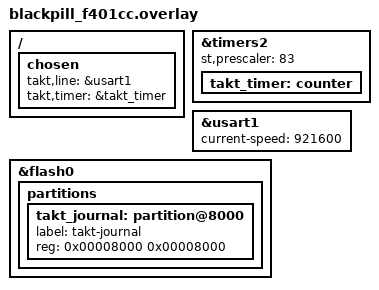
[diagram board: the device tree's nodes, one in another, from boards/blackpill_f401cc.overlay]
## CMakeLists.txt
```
# Takt unter Zephyr (12.11, M11 Schritt 19): das Pruefprogramm der
# Portpruefung als Baustein einer Zephyr-Anwendung, auf `blackpill_f401cc`
# und `esp32c6_devkitc/esp32c6/hpcore`.
#
#   west build -b blackpill_f401cc examples/zephyr --
#       -DTAKT_EXECUTABLE=<takt> -DTAKT_SDK_LIBRARY=<SDK-Archiv des Ziels>
#
# Das SDK-Archiv ist fuer das Tripel aus `CONFIG_TAKT_TARGET` gebaut
# (`cargo rustc --release --lib --crate-type staticlib --target TRIPEL
# --manifest-path crates/takt-embed-c/Cargo.toml`). Das Modul ist die Wurzel
# von Takt (`zephyr/module.yml`); eine Anwendung ausserhalb nimmt es ueber
# ihr west-Manifest oder `ZEPHYR_EXTRA_MODULES`.

cmake_minimum_required(VERSION 3.20.0)

set(TAKT_ROOT ${CMAKE_CURRENT_LIST_DIR}/../..)
list(APPEND ZEPHYR_EXTRA_MODULES ${TAKT_ROOT})
find_package(Zephyr REQUIRED HINTS $ENV{ZEPHYR_BASE})
project(takt_zephyr C)

# Die Hardware-Konfiguration des Boards (8.10): Kalibrierung, Stack-Reserve
# der Form `rtos`, Journal.
if(BOARD STREQUAL "blackpill_f401cc")
  set(hardware ${TAKT_ROOT}/corpus-try/hw/stm32f401.hw)
elseif(BOARD STREQUAL "esp32c6_devkitc")
  set(hardware ${TAKT_ROOT}/corpus-try/hw/esp32c6.hw)
else()
  message(FATAL_ERROR "examples/zephyr: keine Hardware-Konfiguration fuer ${BOARD}")
endif()

# Im Sim-Build, wie `takt port-test --emit embed` es liefert: Die Ausgaenge
# gehen ohne Treiber in den Trace.
takt_add_program(port_test SOURCE ${TAKT_ROOT}/corpus-try/124_port_test.takt HARDWARE ${hardware} BUILD sim)

target_sources(app PRIVATE src/main.c src/line.c src/handback.c src/partition.c)
if(BOARD STREQUAL "blackpill_f401cc")
  target_sources(app PRIVATE src/handback_stm32f401.c)
else()
  target_sources(app PRIVATE src/handback_reboot.c)
endif()
target_link_libraries(app PRIVATE port_test)

# Ein frisches Journal fuer die Portpruefung, die mit dem Interpreter ohne
# gespeicherte Werte vergleicht; ohne ueberlebt `persist` einen Neustart.
option(TAKT_FRESH_JOURNAL "das Journal vor dem Lauf loeschen" OFF)
if(TAKT_FRESH_JOURNAL)
  target_compile_definitions(app PRIVATE TAKT_FRESH_JOURNAL=1)
else()
  target_compile_definitions(app PRIVATE TAKT_FRESH_JOURNAL=0)
endif()

# Eine zweite Probe der Partition im Lauf: Der Kern meldet sie als
# `Runtime(Hardware)` (12.3); fuer den Board-Test, nicht fuer die Portpruefung.
option(TAKT_PROBE_IN_RUN "die Partition auch im Lauf proben" OFF)
if(TAKT_PROBE_IN_RUN)
  target_compile_definitions(app PRIVATE TAKT_PROBE_IN_RUN=1)
else()
  target_compile_definitions(app PRIVATE TAKT_PROBE_IN_RUN=0)
endif()
```

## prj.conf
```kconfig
# Takt unter Zephyr (12.11): das Modul, die Leitung und die fremde Last.
CONFIG_TAKT=y

# Das Journal (5.9) im Flash, in der Partition `takt_journal` des
# Devicetree (boards/*.overlay).
CONFIG_TAKT_JOURNAL_FLASH=y

# Die Leitung (12.2, 12.5): das UART-Geraet `takt,line` des Devicetree,
# gesendet aus seinem Interrupt, damit der Schritt nie auf sie wartet.
CONFIG_SERIAL=y
CONFIG_UART_INTERRUPT_DRIVEN=y
CONFIG_RING_BUFFER=y

# Die Arena in einer eigenen Partition, die keine Domaene eines Fadens im
# Benutzermodus enthaelt (12.11, `Schutz: Partition`).
CONFIG_USERSPACE=y

# Die Uhr des Ports ist ein Zaehler, den boards/*.overlay als `takt,timer`
# waehlt (FB-733); ohne ihn waere die Frist auf einen Systemtick genau.
CONFIG_COUNTER=y
CONFIG_SYS_CLOCK_TICKS_PER_SEC=100000

# `main` rechnet die fremde Last unter dem Jobfaden und schreibt am Ende die
# Bilanz (`takt_core_report`).
CONFIG_MAIN_THREAD_PRIORITY=14
CONFIG_MAIN_STACK_SIZE=4096
```

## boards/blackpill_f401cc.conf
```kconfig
# Board 1 (plan/f401.md): Sektor 0 haelt der HID-Bootloader, Sektor 1 das
# Sprungbrett, Sektor 2 und 3 das Journal; die Anwendung beginnt in Sektor 4
# (0x0801_0000), wo das Sprungbrett sie startet, und hat 192 KiB.
CONFIG_FLASH_LOAD_OFFSET=0x10000
CONFIG_FLASH_LOAD_SIZE=0x30000

# Die FPU mit der ABI des Tripels `thumbv7em-none-eabihf`; `CONFIG_TAKT`
# waehlt dazu `CONFIG_FPU_SHARING`.
CONFIG_FPU=y
CONFIG_FP_HARDABI=y

# USART1 ist die Leitung, keine Konsole daneben.
CONFIG_CONSOLE=n
CONFIG_UART_CONSOLE=n
```

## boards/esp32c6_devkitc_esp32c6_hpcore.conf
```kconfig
# Board 2: `TAKT` auf der Leitung startet das Board neu (src/handback_reboot.c).
CONFIG_REBOOT=y
```

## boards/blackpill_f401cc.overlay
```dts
/* Board 1: die Leitung auf USART1 (PA9/PA10) mit der Rate aller
 * F401-Programme, die der Host ohne Wissen um das laufende erreicht, und
 * TIM2 als Uhr des Ports. Das
 * Journal in Sektor 2 und 3 (je 16 KiB ab 0x0800_8000), wo es auch die
 * Bring-ups halten: zwischen Sprungbrett und Anwendung, und kein Abbild
 * schreibt dorthin. */
/ {
	chosen {
		takt,line = &usart1;
		takt,timer = &takt_timer;
	};
};

/* Die Uhr des Ports (FB-733): TIM2, 32 Bit, mit 1 MHz wie die
 * Interruptform in Rust (`takt_board_stm32f401::TIMER_HZ`); 84 MHz
 * Timertakt durch 84. */
&timers2 {
	st,prescaler = <83>;
	status = "okay";

	takt_timer: counter {
		status = "okay";
	};
};

&usart1 {
	current-speed = <921600>;
};

&flash0 {
	partitions {
		takt_journal: partition@8000 {
			label = "takt-journal";
			reg = <0x00008000 0x00008000>;
		};
	};
};
```

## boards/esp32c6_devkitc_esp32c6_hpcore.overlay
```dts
/* Board 2 (plan/esp32c6.md): ein ESP32-C6-DevKitM-1-N4, dessen Modul
 * ESP32-C6-MINI-1 4 MB Flash hat; `esp32c6_devkitc` nimmt 8 MB an, und der
 * Kopf des Abbilds nennte dem ROM-Lader die falsche Groesse. Die Leitung
 * ist der USB-Serial-JTAG, wie in den Bring-ups; die Konsole bleibt auf
 * UART0.
 *
 * Das Journal in zwei Sektoren zu 4 KiB am Anfang der Partition `storage`
 * (0x3b_0000), die sonst niemand nutzt: Das Abbild liegt ab 0x0 (Simple
 * Boot) und reicht ueber 0x9000, wo die Bring-ups ihr Journal halten. */
/delete-node/ &storage_partition;

/ {
	chosen {
		takt,line = &usb_serial;
		takt,timer = &takt_timer;
	};
};

/* Die Uhr des Ports (FB-733): Timer 0 der Gruppe 0 mit 1 MHz, 80 MHz
 * Takt der Quelle durch 80; ein Tick ist 1000 ns. Der Treiber der
 * `counter`-API haengt am Kind `counter`, den Teiler traegt der Timer. */
&timer0 {
	prescaler = <80>;
	status = "okay";

	takt_timer: counter {
		status = "okay";
	};
};

&flash0 {
	reg = <0x0 DT_SIZE_M(4)>;

	partitions {
		takt_journal: partition@3b0000 {
			label = "takt-journal";
			reg = <0x3b0000 DT_SIZE_K(8)>;
		};
	};
};

&usb_serial {
	status = "okay";
};
```

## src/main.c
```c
/* Takt unter Zephyr: das Pruefprogramm der Portpruefung (12.11, 13.8; M11
 * Schritt 19).
 *
 * `takt_add_program` liefert `port_test` (Bibliothek, `port_test.h`,
 * `takt_sdk.h`), das SDK-Archiv bringt den Kern, das Modul den Port. Diese
 * Anwendung stellt, was der Wirt stellt (12.11): die Leitung, den Watchdog,
 * das Geraet des Journals, beide Stacks und die Arena in ihrer Partition.
 * Vor dem Lauf belegt eine Probe im Benutzermodus, dass die Partition sie
 * abweist (Kopfzeile `takt schutz partition …`). Waehrend des Laufs rechnet
 * `main` die fremde Last, danach schreibt es die Bilanz, und `takt port-test
 * --judge` urteilt ueber alles, was ueber die Leitung kam.
 */
#include <stdint.h>

#include <zephyr/kernel.h>
#include <zephyr/sys/printk.h>

#include "handback.h"
#include "line.h"
#include "partition.h"
#include "port_test.h"
#include "takt_rtos.h"
#include "takt_sdk.h"
#include "takt_zephyr_nvm.h"

/* So viele Ticks faehrt der Port: `takt_conformance::port::TICKS`. */
#define TICKS 2000U

/* Der Watchdog des Wirts (12.11): Dieses Beispiel startet keinen. Ein Wirt
 * mit einem fuettert hier den Task-Watchdog (`task_wdt_feed`) oder den der
 * Hardware (`wdt_feed`). */
static void kick(void *ctx) {
    ARG_UNUSED(ctx);
}

/* Oeffnet das Geraet des Journals (5.9): zwei Slots im Flash, in der
 * Partition `takt_journal` des Devicetree (`ports/zephyr-nvm`, FB-732). Ein
 * Bau mit `TAKT_FRESH_JOURNAL` loescht sie vor dem Lauf: Die Portpruefung
 * vergleicht mit dem Interpreter ohne gespeicherte Werte; ohne ueberlebt
 * `persist` einen Neustart. 0 oder -errno. */
static int journal_open(struct takt_nvm *nvm) {
    static struct takt_zephyr_nvm journal;
    int rc = takt_zephyr_nvm_open(&journal, PARTITION_ID(takt_journal), PORT_TEST_NVM_BLOCKING_NS, nvm);
    if ((rc == 0) && (TAKT_FRESH_JOURNAL != 0)) {
        rc = takt_zephyr_nvm_clear(&journal);
    }
    return rc;
}

/* Luft ueber der Schranke des Programms in jedem Stack, damit eine tiefere
 * Messung im Urteil steht, statt dass der Stackwaechter sie als Fault
 * meldet (12.3). */
#define STACK_SLACK 1024U

/* Die Arena in ihrer Partition (12.11): `init` beschreibt sie ganz, darum
 * im Abschnitt ohne Anfangswerte. */
K_APP_BMEM(takt_arena) static struct port_test_arena arena;

/* Was die Probe der Partition sah, als Kopfzeile vor der Marke. */
static const char *protection(void) {
    const int seen = partition_probe(&arena);
    const char *line = "takt schutz partition ungeprueft\n";
    if (seen == PARTITION_REFUSED) {
        line = "takt schutz partition verweigert\n";
    } else if (seen == PARTITION_OPEN) {
        line = "takt schutz partition offen\n";
    } else {
        /* Die Probe endete nicht: kein Urteil. */
    }
    return line;
}

/* Ein Schritt vor dem Lauf scheiterte: Er steht mit seinem Code auf der
 * Leitung, bevor das Board auf den Host wartet. Ohne `takt_line_flush`
 * bliebe er im Ring, denn den gibt der Kern erst nach einem Tick ab, und
 * die Leitung schwiege (FB-757). */
static void refused(const char *what, int32_t code) {
    takt_board_trace(what);
    takt_board_trace_i64(code);
    takt_board_trace("\n");
    takt_line_flush();
}

/* Die Uhr des Ports als Kopfzeile: Quelle und Rate (FB-733), etwa
 * `takt uhr counter 1000000 Hz`. */
static void clock_line(void) {
    char line[48];
    uint32_t hz = 0U;
    const char *source = takt_os_clock(&hz);
    (void)snprintk(line, sizeof line, "takt uhr %s %u Hz\n", source, (unsigned int)hz);
    takt_board_trace(line);
}

/* Faehrt den Kern `core` ueber den Port, waehrend `main` die fremde Last
 * rechnet, und schreibt die Bilanz. Verlangt der Host das Board zurueck,
 * gibt `main` es sofort ab. Startet der Port nicht oder misst er die Stacks
 * nicht, steht die Bilanz trotzdem da, und das Urteil nennt, was fehlt. */
static void drive(takt_core *core) {
    /* Kernel-Stacks fuer Supervisor-Faeden (`ports/zephyr/takt_os_types.h`). */
    static K_KERNEL_STACK_DEFINE(tick_stack, PORT_TEST_TICK_STACK_BYTES + STACK_SLACK);
    static K_KERNEL_STACK_DEFINE(job_stack, PORT_TEST_JOB_STACK_BYTES + STACK_SLACK);
    static struct takt_rtos rtos;
    const struct takt_rtos_config config = {
        .ticks = TICKS,
        .tick_ns = PORT_TEST_TICK_NS,
        .tick_stack = tick_stack,
        .tick_stack_bytes = sizeof tick_stack,
        .job_stack = job_stack,
        .job_stack_bytes = sizeof job_stack,
        .step_priority = TAKT_OS_STEP_PRIORITY,
        .job_priority = TAKT_OS_JOB_PRIORITY,
    };
    takt_foreign foreign = {0U, 0U};
    struct takt_stacks stacks;
    const struct takt_stacks *measured = NULL;
    if (takt_rtos_start(&rtos, core, &config) == 0) {
#if TAKT_PROBE_IN_RUN
        /* Ein Bau mit `TAKT_PROBE_IN_RUN` probt die Partition noch einmal im
         * Lauf: Die Schutzeinheit weist den Zugriff ab, und der Kern meldet
         * `Runtime(Hardware)` (12.3, `partition_guard`). */
        (void)partition_probe(&arena);
#endif
        /* Die fremde Aufgabe: rechnet mit der FPU, solange Takt laeuft. */
        while (takt_rtos_running(&rtos) != 0) {
            takt_foreign_round(&foreign);
            handback_serve();
        }
        if (takt_rtos_join(&rtos, &stacks) == 0) {
            stacks.tick_bound = PORT_TEST_TICK_STACK_BYTES;
            stacks.job_bound = PORT_TEST_JOB_STACK_BYTES;
            measured = &stacks;
        }
    } else {
        takt_board_trace("takt port: kein Start\n");
    }
    takt_core_report(core, measured, &foreign);
}

int main(void) {
    static uint8_t ring[4096];
    static uint8_t current[PORT_TEST_PERSIST_BOUND];
    static uint8_t stored[PORT_TEST_PERSIST_BOUND];
    static takt_core core;
    static struct takt_nvm nvm;
    static const struct takt_watchdog watchdog = {NULL, kick};
    struct takt_line line;
    if ((line_open(&line) == 0) && (takt_line_init(&line, ring, sizeof ring) == TAKT_OK)) {
        int rc;
        /* Jede Zeile des Kopfs geht gleich an die Leitung: Steht der Start
         * danach, zeigt sie, wie weit er kam (FB-757). */
        takt_board_trace("takt auf zephyr\n" TAKT_RTOS_PROTECTION "\n");
        takt_line_flush();
        takt_board_trace(protection());
        clock_line();
        takt_line_mark();
        takt_line_flush();
        rc = journal_open(&nvm);
        if (rc != 0) {
            refused("takt journal: nicht offen ", rc);
        } else {
            const int32_t status =
                takt_core_init_journaled(&core, &port_test_ops, &arena, NULL, TAKT_PROFILE_SHARED, &watchdog, &nvm,
                                         current, stored, PORT_TEST_PERSIST_BOUND);
            if (status != TAKT_OK) {
                refused("takt kern: nicht bereit ", status);
            } else {
                partition_guard(&core);
                drive(&core);
            }
        }
    }
    handback_await();
    return 0;
}
```

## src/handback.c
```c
/* handback.c - der Wunsch des Hosts nach dem Board (handback.h). */
#include "handback.h"

#include <zephyr/kernel.h>

static K_SEM_DEFINE(handback_wished, 0, 1);

void handback_wish(void) {
    k_sem_give(&handback_wished);
}

void handback_serve(void) {
    if (k_sem_take(&handback_wished, K_NO_WAIT) == 0) {
        handback_give();
    }
}

void handback_await(void) {
    (void)k_sem_take(&handback_wished, K_FOREVER);
    handback_give();
}
```

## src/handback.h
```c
/* handback.h - das Board zurueck an den Host (FB-275): Schreibt der Host
 * `TAKT` auf die Leitung, gibt die Anwendung das Board ab, damit er das
 * naechste Abbild ohne Hand schreibt. Was das heisst, haengt am Board: der
 * F401 startet mit dem Wunsch nach dem DFU-Bootloader des ROM neu, und das
 * Sprungbrett springt hinein (handback_stm32f401.c); jedes andere startet
 * neu (handback_reboot.c). Den Wunsch des Hosts nimmt handback.c an. */
#ifndef HANDBACK_H
#define HANDBACK_H

#include <zephyr/toolchain.h>

/* Der Host hat `TAKT` geschrieben; aus der ISR der Leitung. */
void handback_wish(void);

/* Gibt das Board ab, wenn der Host es verlangt hat; sonst kehrt sie zurueck.
 * Aus einem Faden, nie aus einer ISR. */
void handback_serve(void);

/* Wartet, bis der Host das Board verlangt, und gibt es ab; kehrt nicht
 * zurueck. */
void handback_await(void);

/* Gibt das Board ab, je Board; kehrt nicht zurueck. Aus einem Faden. */
FUNC_NORETURN void handback_give(void);

#endif /* HANDBACK_H */
```

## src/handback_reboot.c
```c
/* handback_reboot.c - ein Board, das der Host ueber seine Debug-Schnittstelle
 * schreibt (ESP32-C6: JTAG des USB-Serial-JTAG), gibt er sich mit einem
 * Neustart zurueck. */
#include "handback.h"

#include <zephyr/sys/reboot.h>

FUNC_NORETURN void handback_give(void) {
    sys_reboot(SYS_REBOOT_COLD);
}
```

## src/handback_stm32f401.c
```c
/* handback_stm32f401.c - Board 1 an den DFU-Bootloader des ROM (AN2606,
 * FB-275, plan/f401.md 2) auf dem gemeinsamen Weg aller Anwendungen
 * (`takt_board_stm32f401::bootloader::request`, `examples/boards/stm32f401`):
 * den Wunsch ins Backup-Register 4, dann ein Neustart.
 *
 * Nach dem Reset laeuft der HID-Bootloader von WeAct, dann das Sprungbrett
 * in Sektor 1 (`takt-trampoline-stm32f401`); das findet den Wunsch und
 * springt in den Systemspeicher. Der Reset raeumt dabei auf, was die
 * Anwendung eingerichtet hat, auch die Regionen der MPU, die Zephyr setzte:
 * Ein Sprung ohne Reset liess sie bis ins naechste Abbild stehen (FB-752). */
#include "handback.h"

#include <soc.h>
#include <zephyr/sys/reboot.h>

/* Der Wunsch nach dem Bootloader, `DFU!` als Wort wie
 * `takt_board_stm32f401::bootloader::REQUESTED`. */
#define HANDBACK_DFU_WISH 0x21554644U

FUNC_NORETURN void handback_give(void) {
    /* Das Backup-Register liegt hinter dem Schreibschutz der Backup-Domaene
     * (RM0368 5.1.2): der Takt von PWR, dann `DBP`. */
    RCC->APB1ENR |= RCC_APB1ENR_PWREN;
    (void)RCC->APB1ENR;
    PWR->CR |= PWR_CR_DBP;
    RTC->BKP4R = HANDBACK_DFU_WISH;
    PWR->CR &= ~PWR_CR_DBP;
    sys_reboot(SYS_REBOOT_COLD);
}
```

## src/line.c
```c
/* line.c - die Leitung auf dem UART-Geraet `takt,line` (line.h).
 *
 * **Ohne zu warten** (12.2): `try_write` legt ein Byte in einen Ring, wenn
 * Platz ist, und der Interrupt des Geraets gibt ihn an dessen Sender weiter.
 * Den Ring davor, das Zaehlen und das Verwerfen macht das SDK.
 *
 * **Die Gegenrichtung liest derselbe Interrupt.** `XOFF` haelt das Senden
 * an, bis `XON` kommt: Der Adapter des F401 meldet so, dass der Host nicht
 * abholt (FB-306); der Trace ist Text, beide Zeichen kommen darin nicht vor.
 * Steht `TAKT` darin, verlangt der Host das Board zurueck (handback.h). */
#include "line.h"

#include <errno.h>
#include <stdint.h>

#include <zephyr/device.h>
#include <zephyr/drivers/uart.h>
#include <zephyr/kernel.h>
#include <zephyr/sys/ring_buffer.h>

#include "handback.h"

/* Was die Leitung ohne Warten annimmt: bei 921600 Baud gut fuenf
 * Millisekunden, mehr als ein Tick des Pruefprogramms schreibt. */
#define LINE_BYTES 512U

/* Hoechstens so viel geht je Interrupt an den Sender: Der USB-Serial-JTAG
 * des C6 nimmt ein Paket nach dem anderen, kuerzer als sein FIFO (FB-264,
 * FB-267); ein USART ohne FIFO nimmt ohnehin ein Byte. */
#define LINE_PACKET 63U

#define XON 0x11U
#define XOFF 0x13U

static const struct device *const line_device = DEVICE_DT_GET(DT_CHOSEN(takt_line));

static struct ring_buf line_ring;

/* Der Host hat `XOFF` gesandt und noch kein `XON`. */
static atomic_t line_paused;

/* Ein Byte der Gegenrichtung. */
static void line_received(const struct device *dev, uint8_t byte) {
    if (byte == XOFF) {
        (void)atomic_set(&line_paused, 1);
    } else if (byte == XON) {
        (void)atomic_set(&line_paused, 0);
        uart_irq_tx_enable(dev);
    } else {
        /* Das Wort, mit dem der Host das Board zurueckverlangt, und wie
         * viele seiner Bytes zuletzt am Stueck kamen. */
        static const uint8_t handback_word[] = {(uint8_t)'T', (uint8_t)'A', (uint8_t)'K', (uint8_t)'T'};
        static size_t matched;
        if (byte == handback_word[matched]) {
            matched++;
        } else {
            matched = (byte == handback_word[0]) ? 1U : 0U;
        }
        if (matched == sizeof handback_word) {
            matched = 0U;
            handback_wish();
        }
    }
}

/* Gibt dem Sender ein Paket; das naechste, wenn er wieder bereit ist. Ist
 * nichts da oder haelt der Host an, schweigt der Interrupt, bis `flush`
 * oder `XON` ihn wieder einschaltet. */
static void line_send(const struct device *dev) {
    uint8_t *bytes = NULL;
    const uint32_t claimed = ring_buf_get_claim(&line_ring, &bytes, LINE_PACKET);
    uint32_t sent = 0U;
    if ((claimed == 0U) || (atomic_get(&line_paused) != 0)) {
        uart_irq_tx_disable(dev);
    } else {
        const int taken = uart_fifo_fill(dev, bytes, (int)claimed);
        sent = (taken > 0) ? (uint32_t)taken : 0U;
    }
    (void)ring_buf_get_finish(&line_ring, sent);
}

/* Je Aufruf: alles Empfangene, und ein Paket an den Sender. */
static void line_isr(const struct device *dev, void *user_data) {
    ARG_UNUSED(user_data);
    if (uart_irq_update(dev) > 0) {
        if (uart_irq_rx_ready(dev) > 0) {
            uint8_t byte = 0U;
            while (uart_fifo_read(dev, &byte, 1) == 1) {
                line_received(dev, byte);
            }
        }
        if (uart_irq_tx_ready(dev) > 0) {
            line_send(dev);
        }
    }
}

static uint8_t line_try_write(void *ctx, uint8_t byte) {
    ARG_UNUSED(ctx);
    return (ring_buf_put(&line_ring, &byte, 1U) == 1U) ? 1U : 0U;
}

static void line_flush(void *ctx) {
    ARG_UNUSED(ctx);
    if ((atomic_get(&line_paused) == 0) && (ring_buf_is_empty(&line_ring) == false)) {
        uart_irq_tx_enable(line_device);
    }
}

int line_open(struct takt_line *line) {
    int rc = -ENODEV;
    if (device_is_ready(line_device)) {
        static uint8_t bytes[LINE_BYTES];
        ring_buf_init(&line_ring, sizeof bytes, bytes);
        rc = uart_irq_callback_user_data_set(line_device, line_isr, NULL);
        if (rc == 0) {
            uart_irq_rx_enable(line_device);
            line->ctx = NULL;
            line->try_write = line_try_write;
            line->flush = line_flush;
        }
    }
    return rc;
}
```

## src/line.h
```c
/* line.h - die Leitung des Wirts (12.2, 12.5) auf dem UART-Geraet, das der
 * Devicetree als `takt,line` waehlt. */
#ifndef LINE_H
#define LINE_H

#include "takt_sdk.h"

/* Richtet das Geraet ein und fuellt `line` mit seinen Rueckrufen; 0 oder
 * -ENODEV, wenn das Geraet nicht bereit ist. */
int line_open(struct takt_line *line);

/* TODO(FB-757): Vermerke fuer die Suche nach dem Stillstand des C6 unter
 * Zephyr; fort, sobald die Ursache behoben ist. Sie gehen nur an eine
 * Konsole neben der Leitung (auf dem C6 UART0), damit der Trace auf der
 * Leitung bleibt, wie das Urteil ihn liest; ohne eine solche tun sie
 * nichts. Waehrend des Laufs schreiben sie nichts: `printk` auf UART0 haelt
 * den Rufenden Millisekunden lang auf und machte Ueberlaeufe. */

/* Vor dem Kern: `takt wecker`, wenn ein Faden mit Frist aufwacht, also der
 * Interrupt des Systemzeitgebers kommt. */
void line_watch_alarm(void);

/* Vor `takt_rtos_start`, nach dem Kern: `takt start`. Mit `ticking` laeuft
 * dazu ein stiller Zeitgeber alle 100 ms, ohne etwas zu schreiben: Haengt
 * der Lauf ohne ihn und laeuft mit ihm, verlor der Systemzeitgeber eine
 * Frist, und erst die naechste Frist eines anderen weckte. */
void line_watch_arm(int ticking);

/* Am Ende des Laufs: `takt ende: <what>` und wie viele Byte der Ring der
 * Leitung noch haelt. */
void line_watch_end(const char *what);

#endif /* LINE_H */
```

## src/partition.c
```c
/* partition.c - die Probe der Partition (partition.h). */
#include "partition.h"

#include <stdint.h>

#include <zephyr/fatal.h>
#include <zephyr/kernel.h>

K_APPMEM_PARTITION_DEFINE(takt_arena);

/* Der Stack der Probe, ein Stack fuer den Benutzermodus. */
#define PROBE_STACK_BYTES 1024U
static K_THREAD_STACK_DEFINE(probe_stack, PROBE_STACK_BYTES);

static struct k_thread probe_thread;

/* Ob der Zugriff der Probe fiel; nur der Fehlerpfad setzt es. */
static atomic_t probe_refused;

/* Der Kern, dem eine Schutzverletzung im Lauf gilt; NULL bis
 * `partition_guard`. */
static takt_core *guarded;

/* Die Probe im Benutzermodus: ein Byte an das Ziel. */
static void probe(void *target, void *unused1, void *unused2) {
    volatile uint8_t *byte = target;
    ARG_UNUSED(unused1);
    ARG_UNUSED(unused2);
    *byte = 0x5AU;
}

/* Der Fehlerpfad des Zephyr-Kerns: Fiel der Zugriff der Probe, haelt er es
 * fest. Faellt im Lauf ein Faden im Benutzermodus, wies die Schutzeinheit
 * seinen Zugriff ab, und der Kern bekommt den Fault (`partition_guard`).
 * Beides kehrt zurueck, und der Zephyr-Kern beendet nur den Faden. Jeden
 * anderen Fehler haelt er an wie die Vorgabe des Zephyr-Kerns. Ob ein Faden
 * im Benutzermodus laeuft, steht in seinen Optionen (`K_USER`); eine
 * Abfrage dafuer hat der Zephyr-Kern nicht. */
void k_sys_fatal_error_handler(unsigned int reason, const struct arch_esf *esf) {
    const struct k_thread *thread = k_current_get();
    const int user = ((thread->base.user_options & K_USER) != 0U) ? 1 : 0;
    ARG_UNUSED(esf);
    if (thread == &probe_thread) {
        (void)atomic_set(&probe_refused, 1);
    }
    if ((user != 0) && (guarded != NULL)) {
        takt_core_hardware_fault(guarded);
    } else if (thread != &probe_thread) {
        k_fatal_halt(reason);
    } else {
        /* Die Probe vor dem Lauf: festgehalten. */
    }
}

void partition_guard(takt_core *core) {
    guarded = core;
}

int partition_probe(void *target) {
    int rc;
    (void)atomic_set(&probe_refused, 0);
    (void)k_thread_create(&probe_thread, probe_stack, K_THREAD_STACK_SIZEOF(probe_stack), probe, target, NULL, NULL,
                          k_thread_priority_get(k_current_get()), K_USER, K_NO_WAIT);
    rc = k_thread_join(&probe_thread, K_SECONDS(1));
    if (rc == 0) {
        rc = (atomic_get(&probe_refused) != 0) ? PARTITION_REFUSED : PARTITION_OPEN;
    }
    return rc;
}
```

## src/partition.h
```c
/* partition.h - die Arena in einer Partition (12.11, `Schutz: Partition`;
 * M11 Schritt 19b). Mit `CONFIG_USERSPACE` liegt die Arena in einer eigenen
 * Partition, die keine Domaene eines Fadens im Benutzermodus enthaelt; die
 * Faeden des Ports sind Supervisor-Faeden und erreichen sie. Die Probe
 * belegt, dass ein Faden im Benutzermodus sie nicht beschreiben kann. Im
 * Lauf meldet jede solche Schutzverletzung dem Kern einen Fault (12.3,
 * `takt_core_hardware_fault`). */
#ifndef PARTITION_H
#define PARTITION_H

#include <zephyr/app_memory/app_memdomain.h>

#include "takt_sdk.h"

/* Die Partition der Arena; `K_APP_DMEM(takt_arena)` legt ein Objekt hinein. */
extern struct k_mem_partition takt_arena;

/* Was die Probe sah. */
#define PARTITION_REFUSED 1 /* der Zugriff fiel, der Faden wurde beendet */
#define PARTITION_OPEN 0    /* der Faden schrieb */

/* Laesst einen Faden im Benutzermodus ein Byte an `target` schreiben und
 * nennt, was geschah; < 0, wenn der Faden nicht endete. Vor
 * `takt_core_init`: Gelaenge der Schreibzugriff, beschriebe `init` die Arena
 * ohnehin neu (12.11). */
int partition_probe(void *target);

/* Ab hier meldet ein Faden im Benutzermodus, dessen Zugriff die
 * Schutzeinheit abweist, dem Kern `core` einen Fault: `Runtime(Hardware)` an
 * seiner naechsten Grenze (12.3); der Zephyr-Kern beendet den Faden. Vorher
 * haelt ein solcher Fehler das Board an, ausser bei der Probe. Nach
 * `takt_core_init`, vor dem Start des Ports. */
void partition_guard(takt_core *core);

#endif /* PARTITION_H */
```
